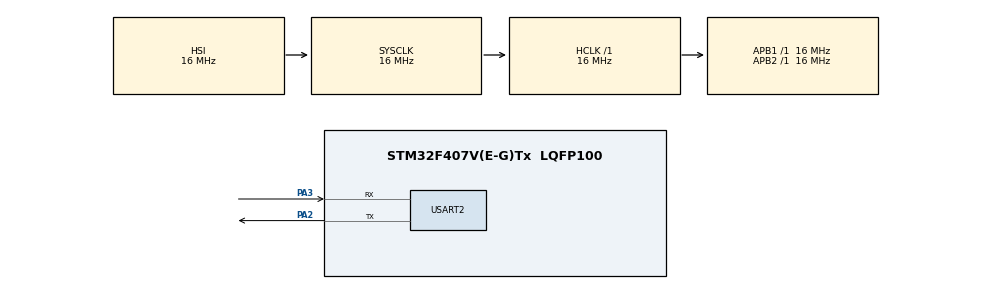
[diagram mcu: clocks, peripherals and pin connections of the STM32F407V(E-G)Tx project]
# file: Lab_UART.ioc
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Mcu.Family=STM32F4
Mcu.Name=STM32F407V(E-G)Tx
Mcu.Package=LQFP100
NVIC.PriorityGroup=NVIC_PRIORITYGROUP_4
NVIC.USART2_IRQn=true\:0\:0\:false\:false\:true\:true\:true\:true
PA13.Mode=Serial_Wire
PA13.Signal=SYS_JTMS-SWDIO
PA14.Mode=Serial_Wire
PA14.Signal=SYS_JTCK-SWCLK
PA2.Mode=Asynchronous
PA2.Signal=USART2_TX
PA3.Mode=Asynchronous
PA3.Signal=USART2_RX
ProjectManager.HeapSize=0x200
ProjectManager.StackSize=0x400
ProjectManager.TargetToolchain=MDK-ARM V5.32
RCC.AHBFreq_Value=16000000
RCC.APB1Freq_Value=16000000
RCC.APB2Freq_Value=16000000
RCC.CortexFreq_Value=16000000
RCC.HSE_VALUE=25000000
RCC.HSI_VALUE=16000000
RCC.LSE_VALUE=32768
RCC.SYSCLKFreq_VALUE=16000000
RCC.VCOOutputFreq_Value=192000000
USART2.Parity=PARITY_NONE
USART2.VirtualMode=VM_ASYNC
USART2.WordLength=WORDLENGTH_8B
board=custom

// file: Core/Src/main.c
/* USER CODE BEGIN Header */
/**
  ******************************************************************************
  * @file           : main.c
  * @brief          : Main program body
  ******************************************************************************
  * @attention
  *
  * Copyright (c) 2023 STMicroelectronics.
  * All rights reserved.
  *
  * This software is licensed under terms that can be found in the LICENSE file
  * in the root directory of this software component.
  * If no LICENSE file comes with this software, it is provided AS-IS.
  *
  ******************************************************************************
  */
/* USER CODE END Header */
#include "main.h"
#include "usart.h"
#include "gpio.h"

/* USER CODE BEGIN Includes */
#include <stdio.h>
#include <string.h>
/* USER CODE END Includes */

/* USER CODE BEGIN PD */
#define PUTCHAR_PROTOTYPE int fputc(int ch, FILE *f)
/* USER CODE END PD */

/* USER CODE BEGIN PM */
PUTCHAR_PROTOTYPE
{
    HAL_UART_Transmit(&huart2, (uint8_t *)&ch, 1, 0xFFFF);
    return ch;
}
/* USER CODE END PM */

/* USER CODE BEGIN PV */
#define BUFFER_SIZE 100
uint8_t input_buffer[BUFFER_SIZE] = {0};
uint8_t index_buffer = 0;
/* USER CODE END PV */

void SystemClock_Config(void);

int main(void)
{

  /* MCU Configuration--------------------------------------------------------*/

  /* Reset of all peripherals, Initializes the Flash interface and the Systick. */
  HAL_Init();

  /* Configure the system clock */
  SystemClock_Config();

  /* Initialize all configured peripherals */
  MX_GPIO_Init();
  MX_USART2_UART_Init();
  /* USER CODE BEGIN 2 */
    uint8_t message[] = "Hello world!\r\n";
    HAL_UART_Transmit(&huart2, message, sizeof(message), 1000);
  /* USER CODE END 2 */

  /* Infinite loop */
  /* USER CODE BEGIN WHILE */
  uint8_t msg[] = {"12:35:00\r"};
  uint8_t hours = 0;
  uint8_t minutes = 0;
  uint8_t seconds = 0;

  HAL_UART_Receive_IT(&huart2, input_buffer, 1);
  while (1)
  {
      seconds ++;
      if (seconds == 60)
      {
          seconds = 0;
          minutes ++;
          if (minutes == 60)
          {
              hours ++;
              if (hours == 24)
              {
                  hours = 0;
              }
          }
      }
//      printf("%2d:%2d:%2d\r", hours, minutes, seconds);
//      HAL_StatusTypeDef status_operation;
//      status_operation = HAL_UART_Receive(&huart2, input_buffer, 5, 1000);
//      switch (status_operation)
//      {
//          case HAL_OK:
//          {
//              printf("HAL_OK\r\n");
//              break;
//          }
//          case HAL_ERROR:
//          {
//              printf("HAL_ERROR\r\n");
//              break;
//          }
//          case HAL_BUSY:
//          {
//              printf("HAL_BUSY\r\n");
//              break;
//          }
//          case HAL_TIMEOUT:
//          {
//              printf("HAL_TIMEOUT\r\n");
//              break;
//          }
//      }
//      HAL_UART_Transmit(&huart2, &msg[0], sizeof(msg), 1);
//      msg[7] ++;
//      if (msg[7] > '9')
//      {
//          msg[6] ++;
//          msg[7] = '0';
//          if (msg[6] > '9')
//          {
//              msg[6] = '0';
//          }
//      }
      HAL_Delay(1000);
    /* USER CODE END WHILE */

  }
}

void SystemClock_Config(void)
{
  RCC_OscInitTypeDef RCC_OscInitStruct = {0};
  RCC_ClkInitTypeDef RCC_ClkInitStruct = {0};

  /** Configure the main internal regulator output voltage
  */
  __HAL_RCC_PWR_CLK_ENABLE();
  __HAL_PWR_VOLTAGESCALING_CONFIG(PWR_REGULATOR_VOLTAGE_SCALE1);

  /** Initializes the RCC Oscillators according to the specified parameters
  * in the RCC_OscInitTypeDef structure.
  */
  RCC_OscInitStruct.OscillatorType = RCC_OSCILLATORTYPE_HSI;
  RCC_OscInitStruct.HSIState = RCC_HSI_ON;
  RCC_OscInitStruct.HSICalibrationValue = RCC_HSICALIBRATION_DEFAULT;
  RCC_OscInitStruct.PLL.PLLState = RCC_PLL_NONE;
  if (HAL_RCC_OscConfig(&RCC_OscInitStruct) != HAL_OK)
  {
    Error_Handler();
  }

  /** Initializes the CPU, AHB and APB buses clocks
  */
  RCC_ClkInitStruct.ClockType = RCC_CLOCKTYPE_HCLK|RCC_CLOCKTYPE_SYSCLK
                              |RCC_CLOCKTYPE_PCLK1|RCC_CLOCKTYPE_PCLK2;
  RCC_ClkInitStruct.SYSCLKSource = RCC_SYSCLKSOURCE_HSI;
  RCC_ClkInitStruct.AHBCLKDivider = RCC_SYSCLK_DIV1;
  RCC_ClkInitStruct.APB1CLKDivider = RCC_HCLK_DIV1;
  RCC_ClkInitStruct.APB2CLKDivider = RCC_HCLK_DIV1;

  if (HAL_RCC_ClockConfig(&RCC_ClkInitStruct, FLASH_LATENCY_0) != HAL_OK)
  {
    Error_Handler();
  }
}

/* USER CODE BEGIN 4 */
void HAL_UART_RxCpltCallback(UART_HandleTypeDef *huart)
{
    if (input_buffer[index_buffer] == '\r')
    {
        printf("\r\n");
        memset(input_buffer, 0, BUFFER_SIZE);
        index_buffer = 0;
    }
    else
    {
        printf("%s\r", input_buffer);
        index_buffer ++;
    }
    HAL_UART_Receive_IT(&huart2, &input_buffer[index_buffer], 1);
}
/* USER CODE END 4 */

void Error_Handler(void)
{
  __disable_irq();
  while (1)
  {
  }
}
